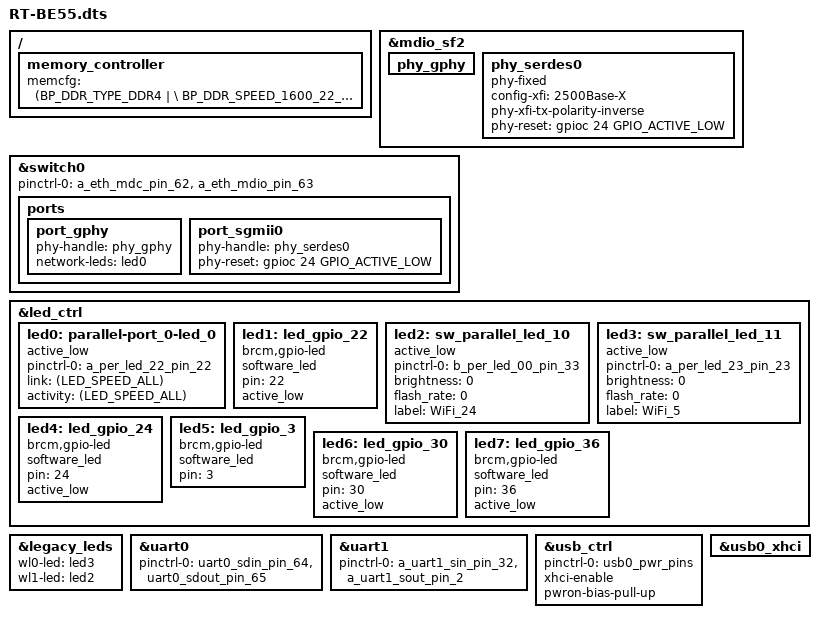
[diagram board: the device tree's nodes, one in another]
#include "6764.dtsi"
#include "../bcm_voice.dtsi"

/ {

	memory_controller {
		memcfg = <(BP_DDR_TYPE_DDR4       | \
			BP_DDR_SPEED_1600_22_22_22    | \
			BP_DDR_TOTAL_SIZE_512MB      | \
			BP_DDR_DEVICE_WIDTH_16         | \
			BP_DDR_TOTAL_WIDTH_16BIT      | \
			BP_DDR_6764_DEFAULT           | \
			BP_DDR_CONFIG_DEBUG)>;
	};

/*
	buttons {
		compatible = "brcm,buttons";
		reset_button {
			ext_irq = <&bca_extintr 39 GPIO_ACTIVE_LOW (BCA_EXTINTR_TYPE_LOW_LEVEL | BCA_EXTINTR_TYPE_SENSE_EDGE)>;
			press {
				print = "Button Press -- Hold for 5s to do restore to default";
			};
			hold {
				rst_to_dflt = <5>;
			};
			release {
				reset = <0>;
			};
		};
		ses_button {
			ext_irq = <&bca_extintr 12 GPIO_ACTIVE_LOW (BCA_EXTINTR_TYPE_LOW_LEVEL | BCA_EXTINTR_TYPE_SENSE_EDGE)>;
			release {
				ses_short_period = <0>;
				ses_long_period = <3>;
			};
		};
	};
*/
};

&mdio_sf2 {
	/* Port PHY mapping:
		port_imp -8#5- port_sgmii0 <--> phy_serdes0 - phy_cascade0 <--> RTL8367S
	 */
	phy_gphy {
		status = "okay";
	};

	phy_serdes0 {
		phy-fixed;
		config-xfi = "2500Base-X";
		phy-xfi-tx-polarity-inverse;
		phy-reset = <&gpioc 24 GPIO_ACTIVE_LOW>;
		status = "okay";
	};

	/* option2
	phy_cascade1 {
		shared-ref-clk-mhz = <80>;
		enet-phy-lane-swap;
		reg = <24>;
		status = "okay";
	};
	phy_serdes1 {
		phy-handle = <&phy_cascade1>;
		phy-xfi-tx-polarity-inverse;
		phy-xfi-rx-polarity-inverse;
		status = "okay";
	};
	*/
};

&switch0 {
	pinctrl-0 = <&a_eth_mdc_pin_62 &a_eth_mdio_pin_63>;
	pinctrl-names = "default";

	ports {
		/* option1: It's best to enable it for bring up */
		port_gphy {
			phy-handle = <&phy_gphy>;
			network-leds=<&led0>;
			status = "okay";
		};

		port_sgmii0 {
			phy-handle = <&phy_serdes0>;
			phy-reset = <&gpioc 24 GPIO_ACTIVE_LOW>;
			status = "okay";
		};

		/* option2
		port_sgmii1 {
			phy-handle = <&phy_serdes1>;
			status = "okay";
		};
		 */
	};
};

&led_ctrl {
	led0: parallel-port_0-led_0 {
		active_low;
		pinctrl-0 = <&a_per_led_22_pin_22>;
		link = <(LED_SPEED_ALL)>;
		activity = <(LED_SPEED_ALL)>;
		status="okay";
	};

	/* WAN ACT LED GPIO mode */
	led1: led_gpio_22 {
		compatible = "brcm,gpio-led";
		software_led;
		pin = <22>;
		active_low;
	};

	led2: sw_parallel_led_10 {
		active_low;
		pinctrl-0 = <&b_per_led_00_pin_33>;
		brightness = <0>;
		flash_rate = <0>;
		status = "okay";
		label = "WiFi_24";
	};

	led3: sw_parallel_led_11 {
		active_low;
		pinctrl-0 = <&a_per_led_23_pin_23>;
		brightness = <0>;
		flash_rate = <0>;
		status = "okay";
		label = "WiFi_5";
	};

	/* RTL8367S reset */
	led4: led_gpio_24 {
		compatible = "brcm,gpio-led";
		software_led;
		pin = <24>;
		active_low;
	};

	/* Power LED */
	led5: led_gpio_3 {
		compatible = "brcm,gpio-led";
		software_led;
		pin = <3>;
	};

	/* WAN Red LED */
	led6: led_gpio_30 {
		compatible = "brcm,gpio-led";
		software_led;
		pin = <30>;
		active_low;
	};

	/* LAN LED */
	led7: led_gpio_36 {
		compatible = "brcm,gpio-led";
		software_led;
		pin = <36>;
		active_low;
	};
};

&legacy_leds {
	wl0-led = <&led3>;
	wl1-led = <&led2>;
};

&uart0 {
	pinctrl-names = "default";
	pinctrl-0 = <&uart0_sdin_pin_64 &uart0_sdout_pin_65>;
	status = "okay";
};

&uart1 {
    pinctrl-names = "default";
    pinctrl-0 = <&a_uart1_sin_pin_32 &a_uart1_sout_pin_2>;
    status = "okay";
};

&usb_ctrl {
	pinctrl-names="default";
	pinctrl-0 = <&usb0_pwr_pins>;
	status = "okay";
	xhci-enable;
	pwron-bias-pull-up;
};
&usb0_xhci {
	status = "okay";
};
